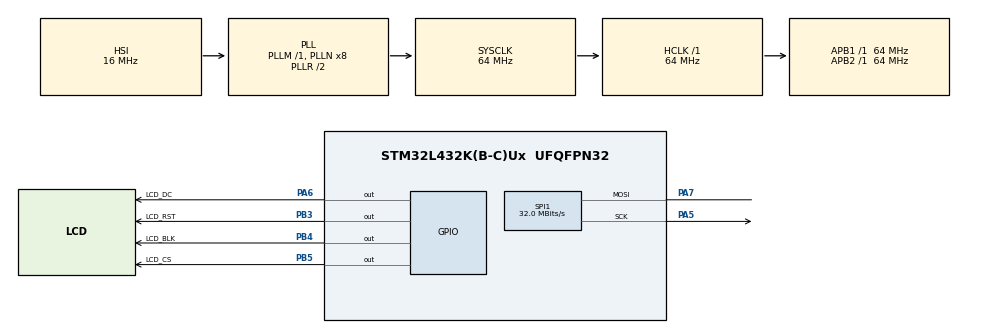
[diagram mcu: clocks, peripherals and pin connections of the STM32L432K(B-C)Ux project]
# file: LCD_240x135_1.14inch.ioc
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Mcu.Family=STM32L4
Mcu.Name=STM32L432K(B-C)Ux
Mcu.Package=UFQFPN32
NVIC.PriorityGroup=NVIC_PRIORITYGROUP_4
PA13\ (JTMS-SWDIO).Mode=Serial_Wire
PA13\ (JTMS-SWDIO).Signal=SYS_JTMS-SWDIO
PA14\ (JTCK-SWCLK).Mode=Serial_Wire
PA14\ (JTCK-SWCLK).Signal=SYS_JTCK-SWCLK
PA5.Mode=Simplex_Bidirectional_Master
PA5.Signal=SPI1_SCK
PA6.GPIO_Label=LCD_DC
PA6.Signal=GPIO_Output
PA7.Mode=Simplex_Bidirectional_Master
PA7.Signal=SPI1_MOSI
PB3\ (JTDO-TRACESWO).GPIO_Label=LCD_RST
PB3\ (JTDO-TRACESWO).Signal=GPIO_Output
PB4\ (NJTRST).GPIO_Label=LCD_BLK
PB4\ (NJTRST).Signal=GPIO_Output
PB5.GPIO_Label=LCD_CS
PB5.Signal=GPIO_Output
ProjectManager.HeapSize=0x200
ProjectManager.StackSize=0x400
ProjectManager.TargetToolchain=MDK-ARM V5.32
RCC.ADCFreq_Value=64000000
RCC.AHBFreq_Value=64000000
RCC.APB1Freq_Value=64000000
RCC.APB1TimFreq_Value=64000000
RCC.APB2Freq_Value=64000000
RCC.APB2TimFreq_Value=64000000
RCC.CortexFreq_Value=64000000
RCC.HCLKFreq_Value=64000000
RCC.HSE_VALUE=8000000
RCC.HSI48_VALUE=48000000
RCC.HSI_VALUE=16000000
RCC.LSE_VALUE=32768
RCC.MSI_VALUE=4000000
RCC.PLLSourceVirtual=RCC_PLLSOURCE_HSI
RCC.SYSCLKFreq_VALUE=64000000
RCC.SYSCLKSource=RCC_SYSCLKSOURCE_PLLCLK
RCC.USBFreq_Value=64000000
RCC.VCOOutputFreq_Value=128000000
SPI1.BaudRatePrescaler=SPI_BAUDRATEPRESCALER_2
SPI1.CLKPhase=SPI_PHASE_1EDGE
SPI1.CLKPolarity=SPI_POLARITY_HIGH
SPI1.CRCCalculation=SPI_CRCCALCULATION_DISABLE
SPI1.CalculateBaudRate=32.0 MBits/s
SPI1.DataSize=SPI_DATASIZE_8BIT
SPI1.Direction=SPI_DIRECTION_1LINE
SPI1.FirstBit=SPI_FIRSTBIT_MSB
SPI1.Mode=SPI_MODE_MASTER
SPI1.NSS=SPI_NSS_SOFT
SPI1.NSSPMode=SPI_NSS_PULSE_ENABLE
SPI1.TIMode=SPI_TIMODE_DISABLE
SPI1.VirtualType=VM_MASTER
board=custom

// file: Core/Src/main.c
/* USER CODE BEGIN Header */
/**
  ******************************************************************************
  * @file           : main.c
  * @brief          : Main program body
  ******************************************************************************
  * @attention
  *
  * <h2><center>&copy; Copyright (c) 2022 STMicroelectronics.
  * All rights reserved.</center></h2>
  *
  * This software component is licensed by ST under BSD 3-Clause license,
  * the "License"; You may not use this file except in compliance with the
  * License. You may obtain a copy of the License at:
  *                        opensource.org/licenses/BSD-3-Clause
  *
  ******************************************************************************
  */
/* USER CODE END Header */
#include "main.h"
#include "spi.h"
#include "gpio.h"

/* USER CODE BEGIN Includes */
#include "lcd.h"
#include "picture.h"
#include "picture1.h"
#include "picture2.h"

/* USER CODE END Includes */

void SystemClock_Config(void);

int main(void)
{

  /* MCU Configuration--------------------------------------------------------*/

  /* Reset of all peripherals, Initializes the Flash interface and the Systick. */
  HAL_Init();

  /* Configure the system clock */
  SystemClock_Config();

  /* Initialize all configured peripherals */
  MX_GPIO_Init();
  MX_SPI1_Init();
  /* USER CODE BEGIN 2 */
	Lcd_Init();
	Lcd_Clear(BLACK);
	Lcd_print( 0,  20,  BLUE, "X Pulse");
	Lcd_print( 0,  50,   RED, "X Pulse");
	Lcd_print( 0,  80, GREEN, "X Pulse");
	Lcd_print(45, 110, LIGHTBLUE, "2023-12-01 00:00:01");
	HAL_Delay(1000);

  /* USER CODE END 2 */

  /* Infinite loop */
  /* USER CODE BEGIN WHILE */
  while (1)
  {
//		Lcd_ShowPicture(0, 0, 240, 135, gImage_picture);
//		HAL_Delay(2000);
//		Lcd_ShowPicture(0, 0, 240, 135, gImage_picture1);
//		HAL_Delay(2000);
//		Lcd_ShowPicture(0, 0, 240, 135, gImage_picture2);
//		HAL_Delay(2000);
    /* USER CODE END WHILE */

  }
}

void SystemClock_Config(void)
{
  RCC_OscInitTypeDef RCC_OscInitStruct = {0};
  RCC_ClkInitTypeDef RCC_ClkInitStruct = {0};

  /** Configure the main internal regulator output voltage
  */
  if (HAL_PWREx_ControlVoltageScaling(PWR_REGULATOR_VOLTAGE_SCALE1) != HAL_OK)
  {
    Error_Handler();
  }

  /** Initializes the RCC Oscillators according to the specified parameters
  * in the RCC_OscInitTypeDef structure.
  */
  RCC_OscInitStruct.OscillatorType = RCC_OSCILLATORTYPE_HSI;
  RCC_OscInitStruct.HSIState = RCC_HSI_ON;
  RCC_OscInitStruct.HSICalibrationValue = RCC_HSICALIBRATION_DEFAULT;
  RCC_OscInitStruct.PLL.PLLState = RCC_PLL_ON;
  RCC_OscInitStruct.PLL.PLLSource = RCC_PLLSOURCE_HSI;
  RCC_OscInitStruct.PLL.PLLM = 1;
  RCC_OscInitStruct.PLL.PLLN = 8;
  RCC_OscInitStruct.PLL.PLLP = RCC_PLLP_DIV7;
  RCC_OscInitStruct.PLL.PLLQ = RCC_PLLQ_DIV2;
  RCC_OscInitStruct.PLL.PLLR = RCC_PLLR_DIV2;
  if (HAL_RCC_OscConfig(&RCC_OscInitStruct) != HAL_OK)
  {
    Error_Handler();
  }

  /** Initializes the CPU, AHB and APB buses clocks
  */
  RCC_ClkInitStruct.ClockType = RCC_CLOCKTYPE_HCLK|RCC_CLOCKTYPE_SYSCLK
                              |RCC_CLOCKTYPE_PCLK1|RCC_CLOCKTYPE_PCLK2;
  RCC_ClkInitStruct.SYSCLKSource = RCC_SYSCLKSOURCE_PLLCLK;
  RCC_ClkInitStruct.AHBCLKDivider = RCC_SYSCLK_DIV1;
  RCC_ClkInitStruct.APB1CLKDivider = RCC_HCLK_DIV1;
  RCC_ClkInitStruct.APB2CLKDivider = RCC_HCLK_DIV1;

  if (HAL_RCC_ClockConfig(&RCC_ClkInitStruct, FLASH_LATENCY_3) != HAL_OK)
  {
    Error_Handler();
  }
}

void Error_Handler(void)
{
  __disable_irq();
  while (1)
  {
  }
}
